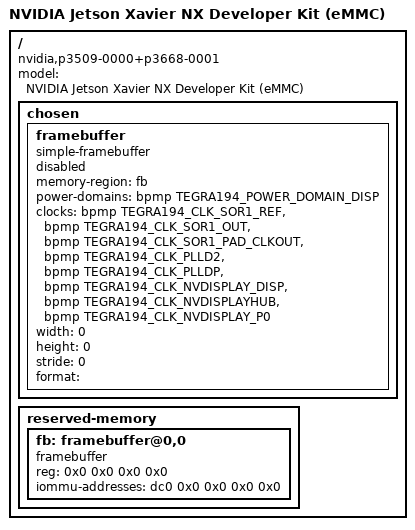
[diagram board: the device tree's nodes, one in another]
// SPDX-License-Identifier: GPL-2.0
/dts-v1/;

#include "tegra194-p3668-0001.dtsi"
#include "tegra194-p3509-0000.dtsi"

/ {
	model = "NVIDIA Jetson Xavier NX Developer Kit (eMMC)";
	compatible = "nvidia,p3509-0000+p3668-0001", "nvidia,tegra194";

	chosen {
		framebuffer {
			compatible = "simple-framebuffer";
			status = "disabled";
			memory-region = <&fb>;
			power-domains = <&bpmp TEGRA194_POWER_DOMAIN_DISP>;
			clocks = <&bpmp TEGRA194_CLK_SOR1_REF>,
				 <&bpmp TEGRA194_CLK_SOR1_OUT>,
				 <&bpmp TEGRA194_CLK_SOR1_PAD_CLKOUT>,
				 <&bpmp TEGRA194_CLK_PLLD2>,
				 <&bpmp TEGRA194_CLK_PLLDP>,
				 <&bpmp TEGRA194_CLK_NVDISPLAY_DISP>,
				 <&bpmp TEGRA194_CLK_NVDISPLAYHUB>,
				 <&bpmp TEGRA194_CLK_NVDISPLAY_P0>;
			width = <0>;
			height = <0>;
			stride = <0>;
			format = "";
		};
	};

	reserved-memory {
		#address-cells = <2>;
		#size-cells = <2>;
		ranges;

		fb: framebuffer@0,0 {
			compatible = "framebuffer";
			reg = <0x0 0x0 0x0 0x0>;
			iommu-addresses = <&dc0 0x0 0x0 0x0 0x0>;
		};
	};
};
